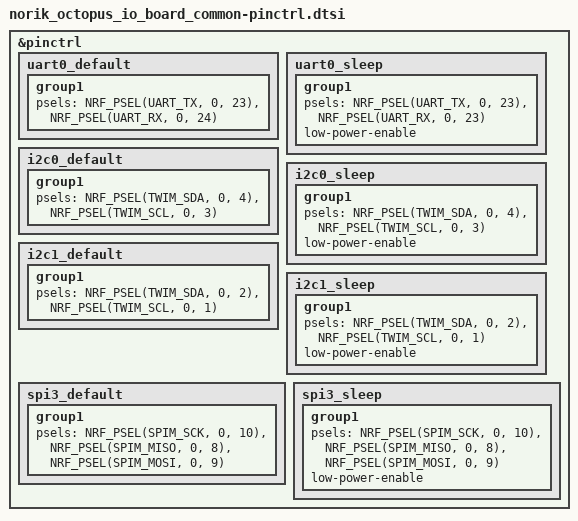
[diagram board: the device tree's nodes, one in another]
/*
 * Copyright (c) 2022 Nordic Semiconductor
 * SPDX-License-Identifier: Apache-2.0
 */

&pinctrl {
	uart0_default: uart0_default {
		group1 {
			psels = <NRF_PSEL(UART_TX, 0, 23)>,
				<NRF_PSEL(UART_RX, 0, 24)>;
		};
	};

	uart0_sleep: uart0_sleep {
		group1 {
			psels = <NRF_PSEL(UART_TX, 0, 23)>,
				<NRF_PSEL(UART_RX, 0, 23)>;
			low-power-enable;
		};
	};
    i2c0_default: i2c0_default {
		group1 {
			psels = <NRF_PSEL(TWIM_SDA, 0, 4)>,
					<NRF_PSEL(TWIM_SCL, 0, 3)>;
		};
	};

	i2c0_sleep: i2c0_sleep {
		group1 {
			psels = <NRF_PSEL(TWIM_SDA, 0, 4)>,
					<NRF_PSEL(TWIM_SCL, 0, 3)>;
			low-power-enable;
		};
	};
    i2c1_default: i2c1_default {
		group1 {
			psels = <NRF_PSEL(TWIM_SDA, 0, 2)>,
					<NRF_PSEL(TWIM_SCL, 0, 1)>;
		};
	};

	i2c1_sleep: i2c1_sleep {
		group1 {
			psels = <NRF_PSEL(TWIM_SDA, 0, 2)>,
					<NRF_PSEL(TWIM_SCL, 0, 1)>;
			low-power-enable;
		};
	};

	spi3_default: spi3_default {
		group1 {
			psels = <NRF_PSEL(SPIM_SCK, 0, 10)>,
				<NRF_PSEL(SPIM_MISO, 0, 8)>,
				<NRF_PSEL(SPIM_MOSI, 0, 9)>;
		};
	};

	spi3_sleep: spi3_sleep {
		group1 {
			psels = <NRF_PSEL(SPIM_SCK, 0, 10)>,
				<NRF_PSEL(SPIM_MISO, 0, 8)>,
				<NRF_PSEL(SPIM_MOSI, 0, 9)>;
			low-power-enable;
		};
	};

};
